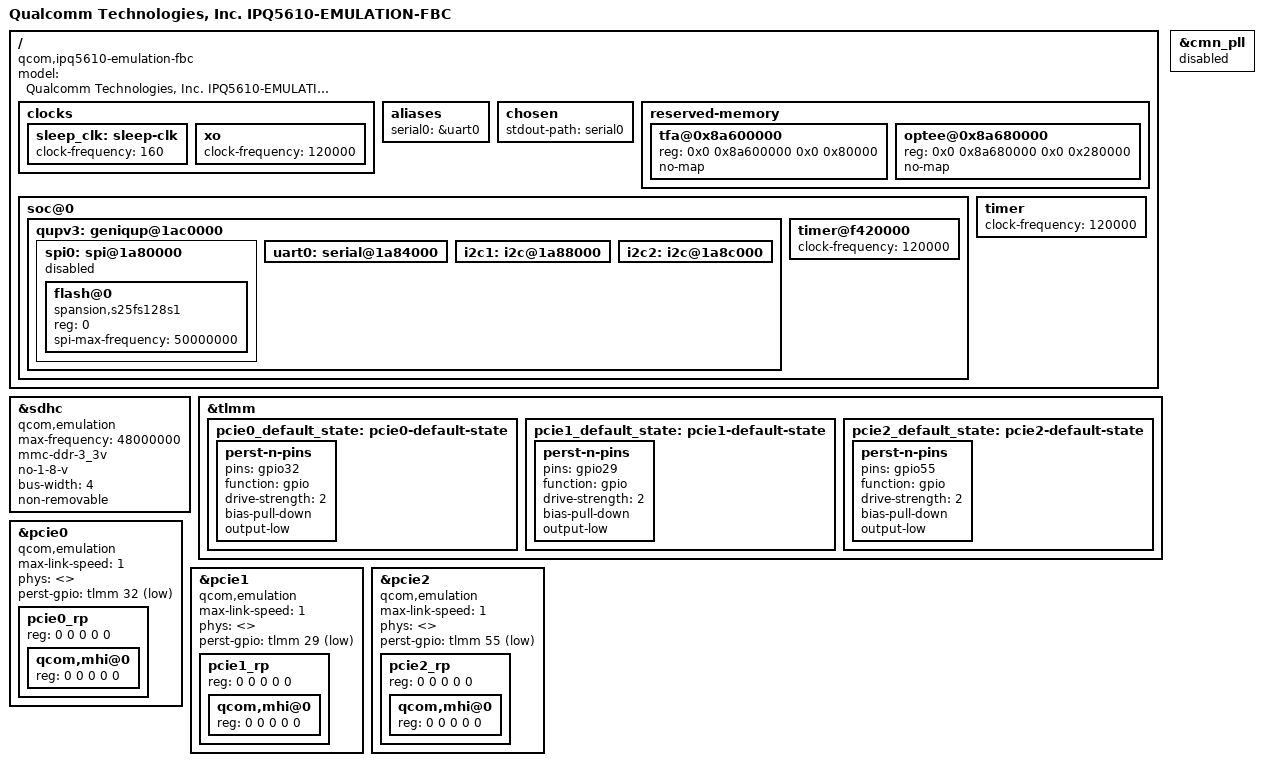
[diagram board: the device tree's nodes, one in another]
// SPDX-License-Identifier: (GPL-2.0+ OR BSD-3-Clause)
/*
 * IPQ5610 Emulation board device tree source
 *
 * Copyright (c) 2020-2021 The Linux Foundation. All rights reserved.
 * Copyright (c) Qualcomm Technologies, Inc. and/or its subsidiaries.
 */

/dts-v1/;

#include "ipq5610.dtsi"

/ {
	model = "Qualcomm Technologies, Inc. IPQ5610-EMULATION-FBC";
	compatible = "qcom,ipq5610-emulation-fbc", "qcom,ipq5610";

	/* Timer freq for rumi = timer freq / 200 */
	clocks {
		/* sleep-clk freq for rumi = sleep-clk freq (32000) / 200 */
		sleep_clk: sleep-clk {
			clock-frequency = <160>;
		};

		/* xo freq for rumi = xo freq (24000000) / 200 */
		xo: xo {
			clock-frequency = <120000>;
		};
	};

	aliases {
		serial0 = &uart0;
	};

	chosen {
		stdout-path = "serial0";
	};

	reserved-memory {
		#address-cells = <2>;
		#size-cells = <2>;
		ranges;

		tfa@0x8a600000 {
			reg = <0x0 0x8a600000 0x0 0x80000>;
			no-map;
		};

		optee@0x8a680000 {
			reg = <0x0 0x8a680000 0x0 0x280000>;
			no-map;
		};
	};

	soc@0 {
		qupv3: geniqup@1ac0000 {
			status = "okay";

			spi0: spi@1a80000 {
				status = "disabled";

				flash@0 {
					compatible = "spansion,s25fs128s1", "jedec,spi-nor";
					#address-cells = <1>;
					#size-cells = <1>;
					reg = <0>;
					spi-max-frequency = <50000000>;
				};
			};

			uart0: serial@1a84000 {
				status = "okay";
			};

			i2c1: i2c@1a88000 {
				status = "okay";
			};

			i2c2: i2c@1a8c000 {
				status = "okay";
			};
		};

		/* Timer freq for rumi = timer freq (24000000) / 200 */
		timer@f420000 {
			clock-frequency = <120000>;
		};
	};

	/* Timer freq for rumi = timer freq (24000000) / 200 */
	timer {
		clock-frequency = <120000>;
	};
};

&sdhc {
	qcom,emulation;
	/* override the frequency to 48Mhz for emulation platform */
	max-frequency = <48000000>;
	/* Force 3.3V, because only that will support on emulation platform */
	mmc-ddr-3_3v;
	/* quirk to disable SDR104, SDR50 modes */
	no-1-8-v;
	bus-width = <4>;
	non-removable;
	status = "okay";
};

&tlmm {
	pcie0_default_state: pcie0-default-state {
		perst-n-pins {
			pins = "gpio32";
			function = "gpio";
			drive-strength = <2>;
			bias-pull-down;
			output-low;
		};
	};

	pcie1_default_state: pcie1-default-state {
		perst-n-pins {
			pins = "gpio29";
			function = "gpio";
			drive-strength = <2>;
			bias-pull-down;
			output-low;
		};
	};

	pcie2_default_state: pcie2-default-state {
		perst-n-pins {
			pins = "gpio55";
			function = "gpio";
			drive-strength = <2>;
			bias-pull-down;
			output-low;
		};
	};
};

&pcie0 {
	qcom,emulation;
	max-link-speed = <1>;
	phys = <>;
	phy-names = "";
	perst-gpio = <&tlmm 32 GPIO_ACTIVE_LOW>;

	pcie0_rp {
		reg = <0 0 0 0 0>;

		qcom,mhi@0 {
			reg = <0 0 0 0 0>;
		};
	};
};

&pcie1 {
	qcom,emulation;
	max-link-speed = <1>;
	phys = <>;
	phy-names = "";
	perst-gpio = <&tlmm 29 GPIO_ACTIVE_LOW>;

	pcie1_rp {
		reg = <0 0 0 0 0>;

		qcom,mhi@0 {
			reg = <0 0 0 0 0>;
		};
	};
};

&pcie2 {
	qcom,emulation;
	max-link-speed = <1>;
	phys = <>;
	phy-names = "";
	perst-gpio = <&tlmm 55 GPIO_ACTIVE_LOW>;

	pcie2_rp {
		reg = <0 0 0 0 0>;

		qcom,mhi@0 {
			reg = <0 0 0 0 0>;
		};
	};
};

&cmn_pll {
	status = "disabled";
};
